AUTOSAR XML (schema 4-2-2)
package /Components
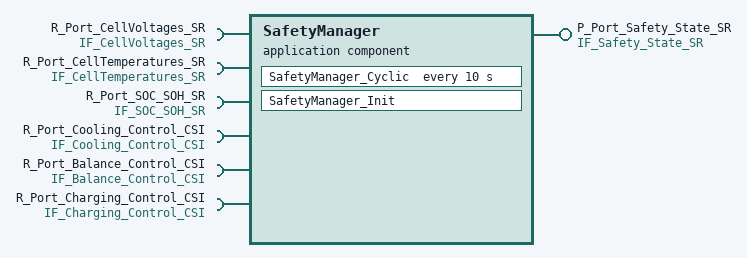
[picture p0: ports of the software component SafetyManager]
  application sw component type SafetyManager
    provide port P_Port_Safety_State_SR: provided-interface=IF_Safety_State_SR
    6 x require port:
      R_Port_CellVoltages_SR: required-interface=IF_CellVoltages_SR
      R_Port_CellTemperatures_SR: required-interface=IF_CellTemperatures_SR
      R_Port_SOC_SOH_SR: required-interface=IF_SOC_SOH_SR
      R_Port_Cooling_Control_CSI: required-interface=IF_Cooling_Control_CSI
      R_Port_Balance_Control_CSI: required-interface=IF_Balance_Control_CSI
      R_Port_Charging_Control_CSI: required-interface=IF_Charging_Control_CSI
    behavior SafetyManager_InternalBehavior
      init event SafetyManager_Init_Event: start-on-event=SafetyManager_Init
      timing event SafetyManager_10ms_Event: start-on-event=SafetyManager_Cyclic, period=10
      runnable SafetyManager_Init
        data-send-points:
          access VA_Init_Send_SafetyState: accessed-variable=P_Port_Safety_State_SR.SafetyState
          access VA_Init_Send_FaultCode: accessed-variable=P_Port_Safety_State_SR.FaultCode
      runnable SafetyManager_Cyclic: minimum-start-interval=10
        data-receive-point-by-values:
          6 x access:
            VA_Cyc_Read_CellVoltages_Array: accessed-variable=R_Port_CellVoltages_SR.CellVoltages_Array
            VA_Cyc_Read_PackVoltage: accessed-variable=R_Port_CellVoltages_SR.PackVoltage
            VA_Cyc_Read_CellTemperatures_Array: accessed-variable=R_Port_CellTemperatures_SR.CellTemperatures_Array
            VA_Cyc_Read_PackTemperature: accessed-variable=R_Port_CellTemperatures_SR.PackTemperature
            VA_Cyc_Read_PackSOC: accessed-variable=R_Port_SOC_SOH_SR.PackSOC
            VA_Cyc_Read_PackSOH: accessed-variable=R_Port_SOC_SOH_SR.PackSOH
        data-send-points:
          access VA_Cyc_Send_SafetyState: accessed-variable=P_Port_Safety_State_SR.SafetyState
          access VA_Cyc_Send_FaultCode: accessed-variable=P_Port_Safety_State_SR.FaultCode
        5 x sync call, all with timeout=20:
          SCP_Cyc_SetCoolantPumpSpeed: operation=R_Port_Cooling_Control_CSI.SetCoolantPumpSpeed
          SCP_Cyc_SetFanSpeed: operation=R_Port_Cooling_Control_CSI.SetFanSpeed
          SCP_Cyc_SuspendBalancing: operation=R_Port_Balance_Control_CSI.SuspendBalancing
          SCP_Cyc_StopCharging: operation=R_Port_Charging_Control_CSI.StopCharging
          SCP_Cyc_SetChargeCurrentLimit: operation=R_Port_Charging_Control_CSI.SetChargeCurrentLimit
